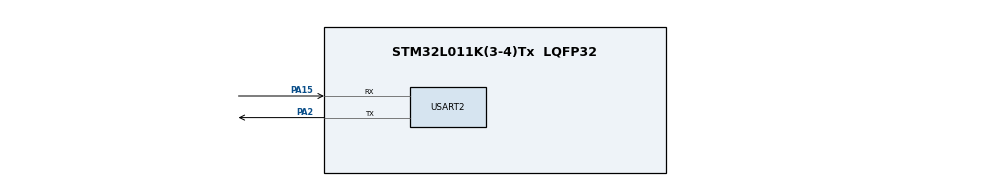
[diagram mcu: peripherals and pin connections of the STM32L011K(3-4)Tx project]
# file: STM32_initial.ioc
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Mcu.Family=STM32L0
Mcu.Name=STM32L011K(3-4)Tx
Mcu.Package=LQFP32
NVIC.RTC_IRQn=true\:1\:0\:true\:false\:true\:true
PA15.Mode=Asynchronous
PA15.Signal=USART2_RX
PA2.Mode=Asynchronous
PA2.Signal=USART2_TX
PC14-OSC32_IN.Mode=LSE-External-Oscillator
PC14-OSC32_IN.Signal=RCC_OSC32_IN
PC15-OSC32_OUT.Mode=LSE-External-Oscillator
PC15-OSC32_OUT.Signal=RCC_OSC32_OUT
ProjectManager.HeapSize=0x200
ProjectManager.StackSize=0x400
ProjectManager.TargetToolchain=Makefile
RCC.AHBFreq_Value=4194000
RCC.APB1Freq_Value=4194000
RCC.APB1TimFreq_Value=4194000
RCC.APB2Freq_Value=4194000
RCC.APB2TimFreq_Value=4194000
RCC.HCLKFreq_Value=4194000
RCC.HSE_VALUE=8000000
RCC.HSI16_VALUE=16000000
RCC.HSI_VALUE=16000000
RCC.MSIClockRange=RCC_MSIRANGE_6
RCC.MSI_VALUE=4194000
RCC.PWR_Regulator_Voltage_Scale=PWR_REGULATOR_VOLTAGE_SCALE3
RCC.RCC_MCOSource=RCC_MCO1SOURCE_MSI
RCC.RTCClockSelection=RCC_RTCCLKSOURCE_LSE
RCC.RTCClockSelectionVirtual=RCC_RTCCLKSOURCE_LSE
RCC.SYSCLKFreq_VALUE=4194000
RCC.Usart2ClockSelection=RCC_USART2CLKSOURCE_SYSCLK
RCC.VCOOutputFreq_Value=48000000
RTC.WakeUpCounter-WakeUp=2048
USART2.VirtualMode-Asynchronous=VM_ASYNC
VP_RTC_VS_RTC_Activate.Mode=RTC_Enabled
VP_RTC_VS_RTC_Calendar.Mode=RTC_Calendar
VP_RTC_VS_RTC_WakeUp_intern.Mode=WakeUp
board=custom

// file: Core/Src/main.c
/**
  ******************************************************************************
  * @file           : main.c
  * @brief          : Main program body
  ******************************************************************************
  ** This notice applies to any and all portions of this file
  * that are not between comment pairs USER CODE BEGIN and
  * USER CODE END. Other portions of this file, whether
  * inserted by the user or by software development tools
  * are owned by their respective copyright owners.
  *
  * COPYRIGHT(c) 2018 STMicroelectronics
  *
  * Redistribution and use in source and binary forms, with or without modification,
  * are permitted provided that the following conditions are met:
  *   1. Redistributions of source code must retain the above copyright notice,
  *      this list of conditions and the following disclaimer.
  *   2. Redistributions in binary form must reproduce the above copyright notice,
  *      this list of conditions and the following disclaimer in the documentation
  *      and/or other materials provided with the distribution.
  *   3. Neither the name of STMicroelectronics nor the names of its contributors
  *      may be used to endorse or promote products derived from this software
  *      without specific prior written permission.
  *
  * THIS SOFTWARE IS PROVIDED BY THE COPYRIGHT HOLDERS AND CONTRIBUTORS "AS IS"
  * AND ANY EXPRESS OR IMPLIED WARRANTIES, INCLUDING, BUT NOT LIMITED TO, THE
  * IMPLIED WARRANTIES OF MERCHANTABILITY AND FITNESS FOR A PARTICULAR PURPOSE ARE
  * DISCLAIMED. IN NO EVENT SHALL THE COPYRIGHT HOLDER OR CONTRIBUTORS BE LIABLE
  * FOR ANY DIRECT, INDIRECT, INCIDENTAL, SPECIAL, EXEMPLARY, OR CONSEQUENTIAL
  * DAMAGES (INCLUDING, BUT NOT LIMITED TO, PROCUREMENT OF SUBSTITUTE GOODS OR
  * SERVICES; LOSS OF USE, DATA, OR PROFITS; OR BUSINESS INTERRUPTION) HOWEVER
  * CAUSED AND ON ANY THEORY OF LIABILITY, WHETHER IN CONTRACT, STRICT LIABILITY,
  * OR TORT (INCLUDING NEGLIGENCE OR OTHERWISE) ARISING IN ANY WAY OUT OF THE USE
  * OF THIS SOFTWARE, EVEN IF ADVISED OF THE POSSIBILITY OF SUCH DAMAGE.
  *
  ******************************************************************************
  */
#include "main.h"
#include "rtc.h"
#include "usart.h"
#include "gpio.h"

/* USER CODE BEGIN Includes */
#include "uart_printf.h"
/* USER CODE END Includes */

/* USER CODE BEGIN PV */
/* Private variables ---------------------------------------------------------*/

/* USER CODE END PV */

static void LL_Init(void);
void SystemClock_Config(void);

/* USER CODE BEGIN PFP */
/* Private function prototypes -----------------------------------------------*/

/* USER CODE END PFP */

int main(void)
{

  /* MCU Configuration----------------------------------------------------------*/

  /* Reset of all peripherals, Initializes the Flash interface and the Systick. */
  LL_Init();

  /* Configure the system clock */
  SystemClock_Config();

  /* Initialize all configured peripherals */
  MX_GPIO_Init();
  MX_RTC_Init();
  MX_USART2_UART_Init();
  /* USER CODE BEGIN 2 */
  uart_print_init();
  tfp_printf("Hello world %d\n", 42);
  MX_RTC_WKUP_Init();

  LL_PWR_EnableLowPowerRunMode();
  LL_PWR_EnterLowPowerRunMode();
  LL_PWR_SetRegulModeLP(LL_PWR_REGU_LPMODES_LOW_POWER);

  SCB->SCR |= SCB_SCR_SLEEPDEEP_Msk; // enable deep sleep for the cortex M0+
  /* USER CODE END 2 */

  /* Infinite loop */
  while (1)
  {
  __WFI();
  }

}
static void LL_Init(void)
{

  LL_APB2_GRP1_EnableClock(LL_APB2_GRP1_PERIPH_SYSCFG);
  LL_APB1_GRP1_EnableClock(LL_APB1_GRP1_PERIPH_PWR);

  /* System interrupt init*/
  /* SVC_IRQn interrupt configuration */
  NVIC_SetPriority(SVC_IRQn, 0);
  /* PendSV_IRQn interrupt configuration */
  NVIC_SetPriority(PendSV_IRQn, 0);
  /* SysTick_IRQn interrupt configuration */
  NVIC_SetPriority(SysTick_IRQn, 0);

}

void SystemClock_Config(void)
{

  LL_FLASH_SetLatency(LL_FLASH_LATENCY_0);

  if(LL_FLASH_GetLatency() != LL_FLASH_LATENCY_0)
  {
  Error_Handler();
  }
  LL_PWR_SetRegulVoltageScaling(LL_PWR_REGU_VOLTAGE_SCALE3);

  LL_RCC_MSI_Enable();

   /* Wait till MSI is ready */
  while(LL_RCC_MSI_IsReady() != 1)
  {

  }
  LL_RCC_MSI_SetRange(LL_RCC_MSIRANGE_6);

  LL_RCC_MSI_SetCalibTrimming(0);

  LL_PWR_EnableBkUpAccess();

  LL_RCC_ForceBackupDomainReset();

  LL_RCC_ReleaseBackupDomainReset();

  LL_RCC_LSE_SetDriveCapability(LL_RCC_LSEDRIVE_LOW);

  LL_RCC_LSE_Enable();

   /* Wait till LSE is ready */
  while(LL_RCC_LSE_IsReady() != 1)
  {

  }
  LL_RCC_SetRTCClockSource(LL_RCC_RTC_CLKSOURCE_LSE);

  LL_RCC_EnableRTC();

  LL_RCC_SetAHBPrescaler(LL_RCC_SYSCLK_DIV_1);

  LL_RCC_SetAPB1Prescaler(LL_RCC_APB1_DIV_1);

  LL_RCC_SetAPB2Prescaler(LL_RCC_APB2_DIV_1);

  LL_RCC_SetSysClkSource(LL_RCC_SYS_CLKSOURCE_MSI);

   /* Wait till System clock is ready */
  while(LL_RCC_GetSysClkSource() != LL_RCC_SYS_CLKSOURCE_STATUS_MSI)
  {

  }
  LL_Init1msTick(4194000);

  LL_SYSTICK_SetClkSource(LL_SYSTICK_CLKSOURCE_HCLK);

  LL_SetSystemCoreClock(4194000);

  LL_RCC_SetUSARTClockSource(LL_RCC_USART2_CLKSOURCE_SYSCLK);

  /* SysTick_IRQn interrupt configuration */
  NVIC_SetPriority(SysTick_IRQn, 0);
}

void _Error_Handler(char *file, int line)
{
  while(1)
  {
  }
}

/************************ (C) COPYRIGHT STMicroelectronics *****END OF FILE****/
